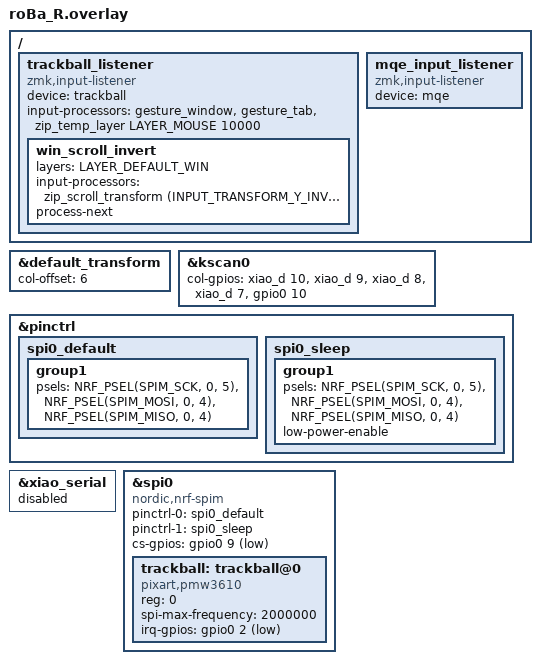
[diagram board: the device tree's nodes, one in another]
#include "roBa.dtsi"
#include <input/processors.dtsi>
#include <dt-bindings/zmk/input_transform.h>

/* config/roBa.keymap のレイヤー定義と一致させること */
#define LAYER_DEFAULT_WIN 1
#define LAYER_MOUSE 5

&default_transform {
    col-offset = <6>;
};

&kscan0 {
        col-gpios
            = <&xiao_d 10 GPIO_ACTIVE_HIGH>
            , <&xiao_d 9 GPIO_ACTIVE_HIGH>
            , <&xiao_d 8 GPIO_ACTIVE_HIGH>
            , <&xiao_d 7 GPIO_ACTIVE_HIGH>
            , <&gpio0 10 GPIO_ACTIVE_HIGH>
            ;
};

/ {
    trackball_listener {
        status = "okay";
        compatible = "zmk,input-listener";
        device = <&trackball>;
        /*
         * Gesture processors run first: while a gesture layer is active they
         * consume motion (STOP) so the cursor stays still and auto-mouse does
         * not trigger. Otherwise they pass through to the auto-mouse temp-layer.
         */
        input-processors = <&gesture_window>, <&gesture_tab>,
                           <&zip_temp_layer LAYER_MOUSE 10000>;

        /*
         * ドライバは CONFIG_PMW3610_INVERT_SCROLL_Y=y でMac向き(ナチュラル)
         * のスクロールを出力する。Windowsモード中はホイールイベントだけ
         * 再反転して従来方向を維持する。process-next を付けないとベースの
         * プロセッサ(ジェスチャー/自動マウスレイヤー)がスキップされる点に注意。
         */
        win_scroll_invert {
            layers = <LAYER_DEFAULT_WIN>;
            input-processors = <&zip_scroll_transform (INPUT_TRANSFORM_Y_INVERT)>;
            process-next;
        };
    };

    mqe_input_listener: mqe_input_listener {
        compatible = "zmk,input-listener";
        device = <&mqe>;
    };
};

&pinctrl {
    spi0_default: spi0_default {
        group1 {
            psels = <NRF_PSEL(SPIM_SCK, 0, 5)>,
                <NRF_PSEL(SPIM_MOSI, 0, 4)>,
                <NRF_PSEL(SPIM_MISO, 0, 4)>;
        };
    };

    spi0_sleep: spi0_sleep {
        group1 {
            psels = <NRF_PSEL(SPIM_SCK, 0, 5)>,
                <NRF_PSEL(SPIM_MOSI, 0, 4)>,
                <NRF_PSEL(SPIM_MISO, 0, 4)>;
            low-power-enable;
        };
    };
};

&xiao_serial { status = "disabled"; };

&spi0 {
    status = "okay";
    compatible = "nordic,nrf-spim";
    pinctrl-0 = <&spi0_default>;
    pinctrl-1 = <&spi0_sleep>;
    pinctrl-names = "default", "sleep";
    cs-gpios = <&gpio0 9 GPIO_ACTIVE_LOW>;

    trackball: trackball@0 {
        status = "okay";
        compatible = "pixart,pmw3610";
        reg = <0>;
        spi-max-frequency = <2000000>;
        irq-gpios = <&gpio0 2 (GPIO_ACTIVE_LOW | GPIO_PULL_UP)>;
    };
};
